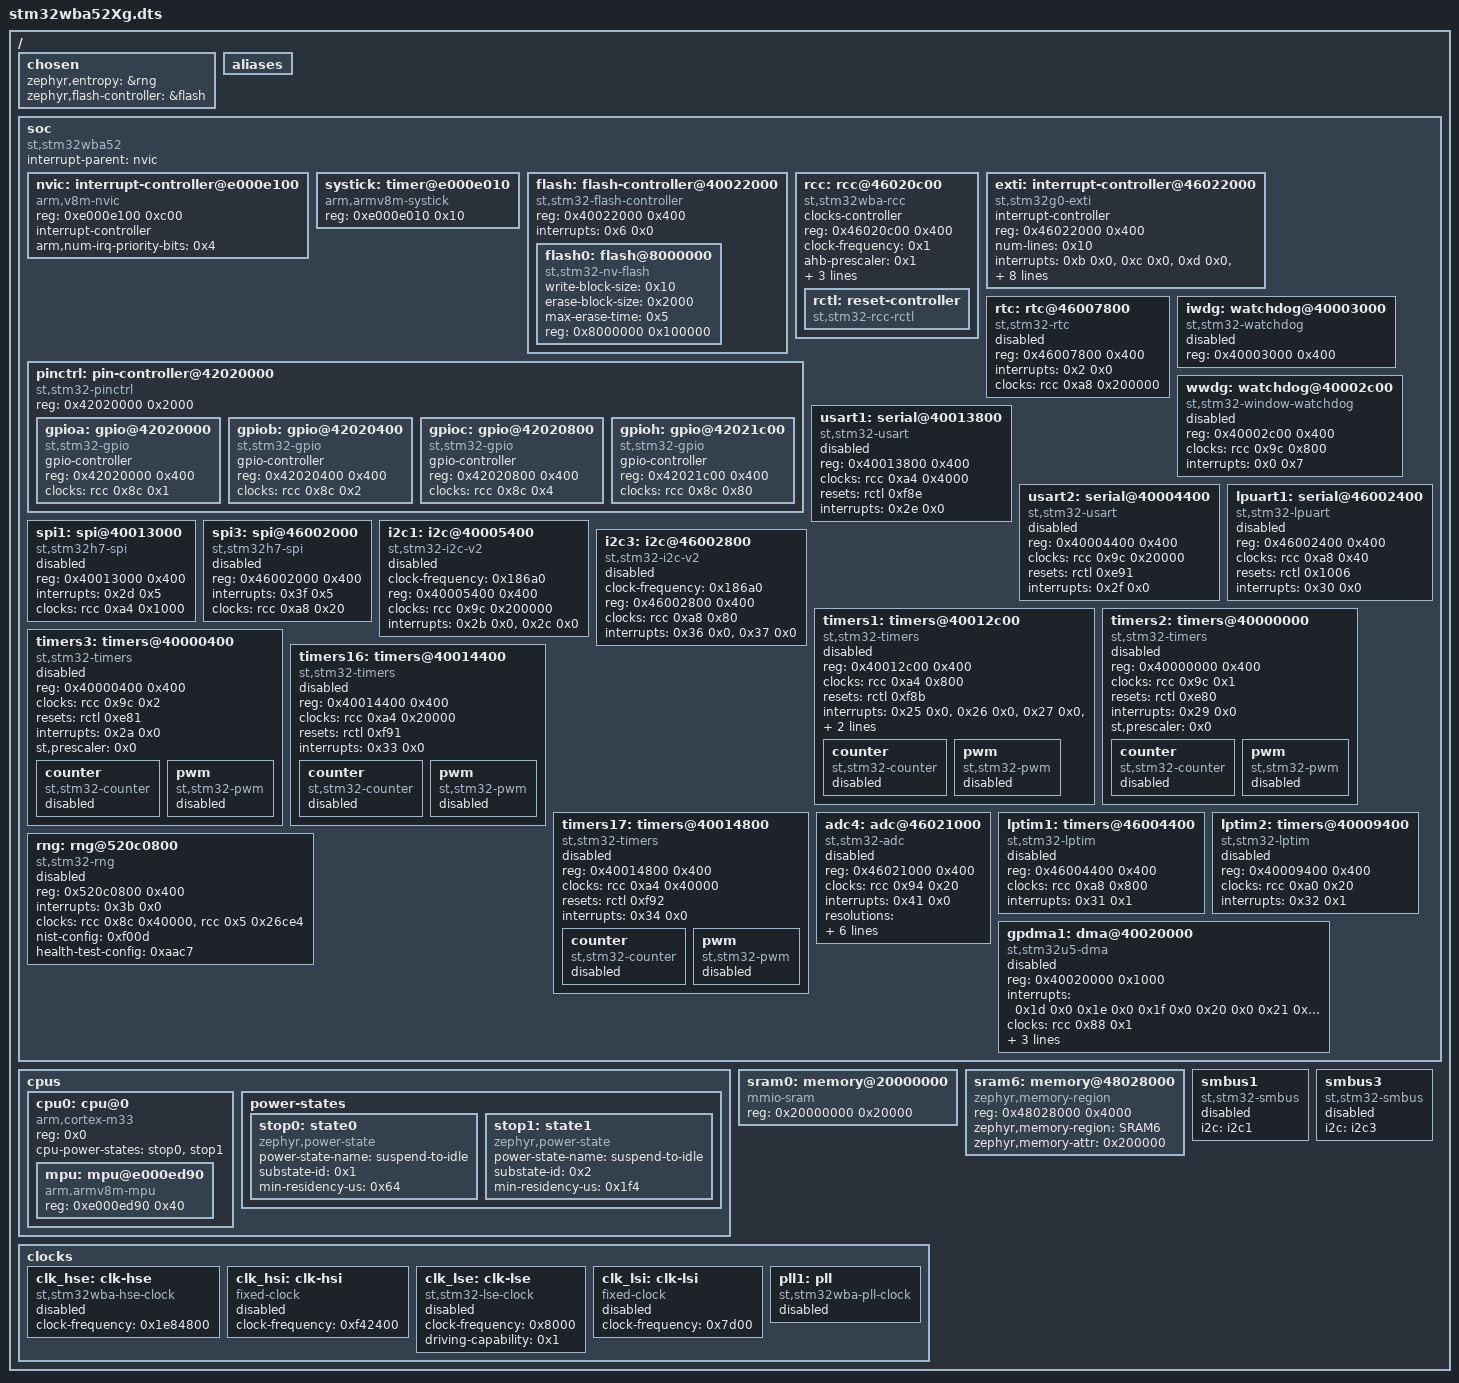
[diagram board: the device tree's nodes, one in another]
/dts-v1/;

/ {
	#address-cells = < 0x1 >;
	#size-cells = < 0x1 >;
	chosen {
		zephyr,entropy = &rng;
		zephyr,flash-controller = &flash;
	};
	aliases {
	};
	soc {
		#address-cells = < 0x1 >;
		#size-cells = < 0x1 >;
		compatible = "st,stm32wba52", "st,stm32wba", "simple-bus";
		interrupt-parent = < &nvic >;
		ranges;
		nvic: interrupt-controller@e000e100 {
			#address-cells = < 0x1 >;
			compatible = "arm,v8m-nvic";
			reg = < 0xe000e100 0xc00 >;
			interrupt-controller;
			#interrupt-cells = < 0x2 >;
			arm,num-irq-priority-bits = < 0x4 >;
			phandle = < 0x1 >;
		};
		systick: timer@e000e010 {
			compatible = "arm,armv8m-systick";
			reg = < 0xe000e010 0x10 >;
		};
		flash: flash-controller@40022000 {
			compatible = "st,stm32-flash-controller", "st,stm32wba-flash-controller";
			reg = < 0x40022000 0x400 >;
			interrupts = < 0x6 0x0 >;
			#address-cells = < 0x1 >;
			#size-cells = < 0x1 >;
			flash0: flash@8000000 {
				compatible = "st,stm32-nv-flash", "soc-nv-flash";
				write-block-size = < 0x10 >;
				erase-block-size = < 0x2000 >;
				max-erase-time = < 0x5 >;
				reg = < 0x8000000 0x100000 >;
			};
		};
		rcc: rcc@46020c00 {
			compatible = "st,stm32wba-rcc";
			clocks-controller;
			#clock-cells = < 0x2 >;
			reg = < 0x46020c00 0x400 >;
			clock-frequency = < 0x1 >;
			ahb-prescaler = < 0x1 >;
			apb1-prescaler = < 0x1 >;
			apb2-prescaler = < 0x1 >;
			apb7-prescaler = < 0x1 >;
			phandle = < 0x2 >;
			rctl: reset-controller {
				compatible = "st,stm32-rcc-rctl";
				#reset-cells = < 0x1 >;
				phandle = < 0x3 >;
			};
		};
		exti: interrupt-controller@46022000 {
			compatible = "st,stm32g0-exti", "st,stm32-exti";
			interrupt-controller;
			#interrupt-cells = < 0x1 >;
			reg = < 0x46022000 0x400 >;
			num-lines = < 0x10 >;
			interrupts = < 0xb 0x0 >, < 0xc 0x0 >, < 0xd 0x0 >, < 0xe 0x0 >, < 0xf 0x0 >, < 0x10 0x0 >, < 0x11 0x0 >, < 0x12 0x0 >, < 0x13 0x0 >, < 0x14 0x0 >, < 0x15 0x0 >, < 0x16 0x0 >, < 0x17 0x0 >, < 0x18 0x0 >, < 0x19 0x0 >, < 0x1a 0x0 >;
			interrupt-names = "line0", "line1", "line2", "line3", "line4", "line5", "line6", "line7", "line8", "line9", "line10", "line11", "line12", "line13", "line14", "line15";
			line-ranges = < 0x0 0x1 >, < 0x1 0x1 >, < 0x2 0x1 >, < 0x3 0x1 >, < 0x4 0x1 >, < 0x5 0x1 >, < 0x6 0x1 >, < 0x7 0x1 >, < 0x8 0x1 >, < 0x9 0x1 >, < 0xa 0x1 >, < 0xb 0x1 >, < 0xc 0x1 >, < 0xd 0x1 >, < 0xe 0x1 >, < 0xf 0x1 >;
		};
		pinctrl: pin-controller@42020000 {
			compatible = "st,stm32-pinctrl";
			#address-cells = < 0x1 >;
			#size-cells = < 0x1 >;
			reg = < 0x42020000 0x2000 >;
			gpioa: gpio@42020000 {
				compatible = "st,stm32-gpio";
				gpio-controller;
				#gpio-cells = < 0x2 >;
				reg = < 0x42020000 0x400 >;
				clocks = < &rcc 0x8c 0x1 >;
			};
			gpiob: gpio@42020400 {
				compatible = "st,stm32-gpio";
				gpio-controller;
				#gpio-cells = < 0x2 >;
				reg = < 0x42020400 0x400 >;
				clocks = < &rcc 0x8c 0x2 >;
			};
			gpioc: gpio@42020800 {
				compatible = "st,stm32-gpio";
				gpio-controller;
				#gpio-cells = < 0x2 >;
				reg = < 0x42020800 0x400 >;
				clocks = < &rcc 0x8c 0x4 >;
			};
			gpioh: gpio@42021c00 {
				compatible = "st,stm32-gpio";
				gpio-controller;
				#gpio-cells = < 0x2 >;
				reg = < 0x42021c00 0x400 >;
				clocks = < &rcc 0x8c 0x80 >;
			};
		};
		rtc: rtc@46007800 {
			compatible = "st,stm32-rtc";
			reg = < 0x46007800 0x400 >;
			interrupts = < 0x2 0x0 >;
			clocks = < &rcc 0xa8 0x200000 >;
			status = "disabled";
		};
		iwdg: watchdog@40003000 {
			compatible = "st,stm32-watchdog";
			reg = < 0x40003000 0x400 >;
			status = "disabled";
		};
		wwdg: watchdog@40002c00 {
			compatible = "st,stm32-window-watchdog";
			reg = < 0x40002c00 0x400 >;
			clocks = < &rcc 0x9c 0x800 >;
			interrupts = < 0x0 0x7 >;
			status = "disabled";
		};
		usart1: serial@40013800 {
			compatible = "st,stm32-usart", "st,stm32-uart";
			reg = < 0x40013800 0x400 >;
			clocks = < &rcc 0xa4 0x4000 >;
			resets = < &rctl 0xf8e >;
			interrupts = < 0x2e 0x0 >;
			status = "disabled";
		};
		usart2: serial@40004400 {
			compatible = "st,stm32-usart", "st,stm32-uart";
			reg = < 0x40004400 0x400 >;
			clocks = < &rcc 0x9c 0x20000 >;
			resets = < &rctl 0xe91 >;
			interrupts = < 0x2f 0x0 >;
			status = "disabled";
		};
		lpuart1: serial@46002400 {
			compatible = "st,stm32-lpuart", "st,stm32-uart";
			reg = < 0x46002400 0x400 >;
			clocks = < &rcc 0xa8 0x40 >;
			resets = < &rctl 0x1006 >;
			interrupts = < 0x30 0x0 >;
			status = "disabled";
		};
		spi1: spi@40013000 {
			compatible = "st,stm32h7-spi", "st,stm32-spi-fifo", "st,stm32-spi";
			#address-cells = < 0x1 >;
			#size-cells = < 0x0 >;
			reg = < 0x40013000 0x400 >;
			interrupts = < 0x2d 0x5 >;
			clocks = < &rcc 0xa4 0x1000 >;
			status = "disabled";
		};
		spi3: spi@46002000 {
			compatible = "st,stm32h7-spi", "st,stm32-spi-fifo", "st,stm32-spi";
			#address-cells = < 0x1 >;
			#size-cells = < 0x0 >;
			reg = < 0x46002000 0x400 >;
			interrupts = < 0x3f 0x5 >;
			clocks = < &rcc 0xa8 0x20 >;
			status = "disabled";
		};
		i2c1: i2c@40005400 {
			compatible = "st,stm32-i2c-v2";
			clock-frequency = < 0x186a0 >;
			#address-cells = < 0x1 >;
			#size-cells = < 0x0 >;
			reg = < 0x40005400 0x400 >;
			clocks = < &rcc 0x9c 0x200000 >;
			interrupts = < 0x2b 0x0 >, < 0x2c 0x0 >;
			interrupt-names = "event", "error";
			status = "disabled";
			phandle = < 0x6 >;
		};
		i2c3: i2c@46002800 {
			compatible = "st,stm32-i2c-v2";
			clock-frequency = < 0x186a0 >;
			#address-cells = < 0x1 >;
			#size-cells = < 0x0 >;
			reg = < 0x46002800 0x400 >;
			clocks = < &rcc 0xa8 0x80 >;
			interrupts = < 0x36 0x0 >, < 0x37 0x0 >;
			interrupt-names = "event", "error";
			status = "disabled";
			phandle = < 0x7 >;
		};
		timers1: timers@40012c00 {
			compatible = "st,stm32-timers";
			reg = < 0x40012c00 0x400 >;
			clocks = < &rcc 0xa4 0x800 >;
			resets = < &rctl 0xf8b >;
			interrupts = < 0x25 0x0 >, < 0x26 0x0 >, < 0x27 0x0 >, < 0x28 0x0 >;
			interrupt-names = "brk", "up", "trgcom", "cc";
			st,prescaler = < 0x0 >;
			status = "disabled";
			counter {
				compatible = "st,stm32-counter";
				status = "disabled";
			};
			pwm {
				compatible = "st,stm32-pwm";
				status = "disabled";
				#pwm-cells = < 0x3 >;
			};
		};
		timers2: timers@40000000 {
			compatible = "st,stm32-timers";
			reg = < 0x40000000 0x400 >;
			clocks = < &rcc 0x9c 0x1 >;
			resets = < &rctl 0xe80 >;
			interrupts = < 0x29 0x0 >;
			interrupt-names = "global";
			st,prescaler = < 0x0 >;
			status = "disabled";
			counter {
				compatible = "st,stm32-counter";
				status = "disabled";
			};
			pwm {
				compatible = "st,stm32-pwm";
				status = "disabled";
				#pwm-cells = < 0x3 >;
			};
		};
		timers3: timers@40000400 {
			compatible = "st,stm32-timers";
			reg = < 0x40000400 0x400 >;
			clocks = < &rcc 0x9c 0x2 >;
			resets = < &rctl 0xe81 >;
			interrupts = < 0x2a 0x0 >;
			interrupt-names = "global";
			st,prescaler = < 0x0 >;
			status = "disabled";
			counter {
				compatible = "st,stm32-counter";
				status = "disabled";
			};
			pwm {
				compatible = "st,stm32-pwm";
				status = "disabled";
				#pwm-cells = < 0x3 >;
			};
		};
		timers16: timers@40014400 {
			compatible = "st,stm32-timers";
			reg = < 0x40014400 0x400 >;
			clocks = < &rcc 0xa4 0x20000 >;
			resets = < &rctl 0xf91 >;
			interrupts = < 0x33 0x0 >;
			interrupt-names = "global";
			status = "disabled";
			counter {
				compatible = "st,stm32-counter";
				status = "disabled";
			};
			pwm {
				compatible = "st,stm32-pwm";
				status = "disabled";
				#pwm-cells = < 0x3 >;
			};
		};
		timers17: timers@40014800 {
			compatible = "st,stm32-timers";
			reg = < 0x40014800 0x400 >;
			clocks = < &rcc 0xa4 0x40000 >;
			resets = < &rctl 0xf92 >;
			interrupts = < 0x34 0x0 >;
			interrupt-names = "global";
			status = "disabled";
			counter {
				compatible = "st,stm32-counter";
				status = "disabled";
			};
			pwm {
				compatible = "st,stm32-pwm";
				status = "disabled";
				#pwm-cells = < 0x3 >;
			};
		};
		adc4: adc@46021000 {
			compatible = "st,stm32-adc";
			reg = < 0x46021000 0x400 >;
			clocks = < &rcc 0x94 0x20 >;
			interrupts = < 0x41 0x0 >;
			status = "disabled";
			#io-channel-cells = < 0x1 >;
			resolutions = < 0x60620c 0x51620c 0x42620c 0x33620c >;
			sampling-times = < 0x2 0x4 0x8 0xd 0x14 0x28 0x50 0x32f >;
			num-sampling-time-common-channels = < 0x2 >;
			st,adc-clock-source = < 0x2 >;
			st,adc-sequencer = < 0x0 >;
		};
		lptim1: timers@46004400 {
			compatible = "st,stm32-lptim";
			#address-cells = < 0x1 >;
			#size-cells = < 0x0 >;
			reg = < 0x46004400 0x400 >;
			clocks = < &rcc 0xa8 0x800 >;
			interrupts = < 0x31 0x1 >;
			interrupt-names = "wakeup";
			status = "disabled";
		};
		lptim2: timers@40009400 {
			compatible = "st,stm32-lptim";
			#address-cells = < 0x1 >;
			#size-cells = < 0x0 >;
			reg = < 0x40009400 0x400 >;
			clocks = < &rcc 0xa0 0x20 >;
			interrupts = < 0x32 0x1 >;
			interrupt-names = "wakeup";
			status = "disabled";
		};
		rng: rng@520c0800 {
			compatible = "st,stm32-rng";
			reg = < 0x520c0800 0x400 >;
			interrupts = < 0x3b 0x0 >;
			clocks = < &rcc 0x8c 0x40000 >, < &rcc 0x5 0x26ce4 >;
			nist-config = < 0xf00d >;
			health-test-config = < 0xaac7 >;
			status = "disabled";
		};
		gpdma1: dma@40020000 {
			compatible = "st,stm32u5-dma";
			#dma-cells = < 0x3 >;
			reg = < 0x40020000 0x1000 >;
			interrupts = < 0x1d 0x0 0x1e 0x0 0x1f 0x0 0x20 0x0 0x21 0x0 0x22 0x0 0x23 0x0 0x24 0x0 >;
			clocks = < &rcc 0x88 0x1 >;
			dma-channels = < 0x8 >;
			dma-requests = < 0x34 >;
			dma-offset = < 0x0 >;
			status = "disabled";
		};
	};
	cpus {
		#address-cells = < 0x1 >;
		#size-cells = < 0x0 >;
		cpu0: cpu@0 {
			device_type = "cpu";
			compatible = "arm,cortex-m33";
			reg = < 0x0 >;
			cpu-power-states = < &stop0 &stop1 >;
			#address-cells = < 0x1 >;
			#size-cells = < 0x1 >;
			mpu: mpu@e000ed90 {
				compatible = "arm,armv8m-mpu";
				reg = < 0xe000ed90 0x40 >;
			};
		};
		power-states {
			stop0: state0 {
				compatible = "zephyr,power-state";
				power-state-name = "suspend-to-idle";
				substate-id = < 0x1 >;
				min-residency-us = < 0x64 >;
				phandle = < 0x4 >;
			};
			stop1: state1 {
				compatible = "zephyr,power-state";
				power-state-name = "suspend-to-idle";
				substate-id = < 0x2 >;
				min-residency-us = < 0x1f4 >;
				phandle = < 0x5 >;
			};
		};
	};
	sram0: memory@20000000 {
		compatible = "mmio-sram";
		reg = < 0x20000000 0x20000 >;
	};
	sram6: memory@48028000 {
		compatible = "zephyr,memory-region", "mmio-sram";
		reg = < 0x48028000 0x4000 >;
		device_type = "memory";
		zephyr,memory-region = "SRAM6";
		zephyr,memory-attr = < 0x200000 >;
	};
	clocks {
		clk_hse: clk-hse {
			#clock-cells = < 0x0 >;
			compatible = "st,stm32wba-hse-clock";
			clock-frequency = < 0x1e84800 >;
			status = "disabled";
		};
		clk_hsi: clk-hsi {
			#clock-cells = < 0x0 >;
			compatible = "fixed-clock";
			clock-frequency = < 0xf42400 >;
			status = "disabled";
		};
		clk_lse: clk-lse {
			#clock-cells = < 0x0 >;
			compatible = "st,stm32-lse-clock";
			clock-frequency = < 0x8000 >;
			driving-capability = < 0x1 >;
			status = "disabled";
		};
		clk_lsi: clk-lsi {
			#clock-cells = < 0x0 >;
			compatible = "fixed-clock";
			clock-frequency = < 0x7d00 >;
			status = "disabled";
		};
		pll1: pll: pll {
			#clock-cells = < 0x0 >;
			compatible = "st,stm32wba-pll-clock";
			status = "disabled";
		};
	};
	smbus1: smbus1 {
		compatible = "st,stm32-smbus";
		#address-cells = < 0x1 >;
		#size-cells = < 0x0 >;
		i2c = < &i2c1 >;
		status = "disabled";
	};
	smbus3: smbus3 {
		compatible = "st,stm32-smbus";
		#address-cells = < 0x1 >;
		#size-cells = < 0x0 >;
		i2c = < &i2c3 >;
		status = "disabled";
	};
};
